# STM32H7x5 register map
File version: 1.1
CPU: CM7 r0p0, little endian, no MPU, no FPU, 3 interrupt priority bits
Registers are 32-bit, read-write, reset 0x0 unless marked. A register's access mark holds for its fields unless they carry their own. Offsets are from the block's base; [hi:lo] are bit positions; {n}, {i} and the like mark numbered series; 'fields as' and 'values as' point back to an identical list.

## BDMA
Base 0x58025400
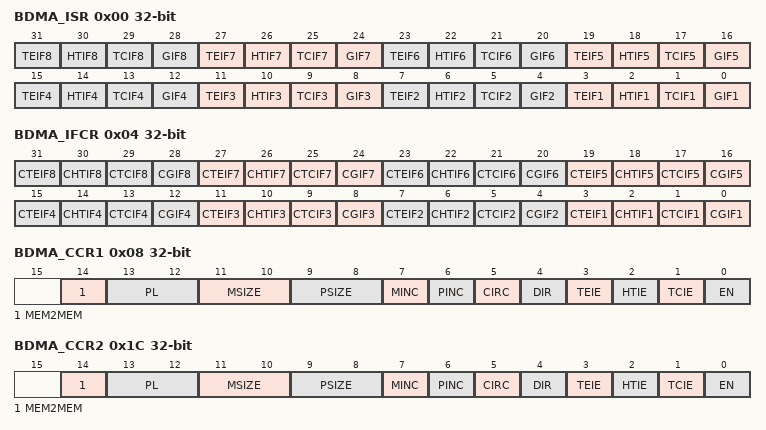
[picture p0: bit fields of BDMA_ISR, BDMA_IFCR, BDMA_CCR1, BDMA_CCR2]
0x00 BDMA_ISR ro — DMA interrupt status register
  [4n-1] TEIF{n} (n=1..8) — Channel x transfer error flag (x = 1..8) This bit is set by hardware. It is cleared by software writing 1 to the corresponding bit in the DMA_IFCR register.
  [4n-2] HTIF{n} (n=1..8) — Channel x half transfer flag (x = 1..8) This bit is set by hardware. It is cleared by software writing 1 to the corresponding bit in the DMA_IFCR register.
  [4n-3] TCIF{n} (n=1..8) — Channel x transfer complete flag (x = 1..8) This bit is set by hardware. It is cleared by software writing 1 to the corresponding bit in the DMA_IFCR register.
  [4n-4] GIF{n} (n=1..8) — Channel x global interrupt flag (x = 1..8) This bit is set by hardware. It is cleared by software writing 1 to the corresponding bit in the DMA_IFCR register.
0x04 BDMA_IFCR wo — DMA interrupt flag clear register
  [4n-1] CTEIF{n} (n=1..8) — Channel x transfer error clear This bit is set and cleared by software.
  [4n-2] CHTIF{n} (n=1..8) — Channel x half transfer clear This bit is set and cleared by software.
  [4n-3] CTCIF{n} (n=1..8) — Channel x transfer complete clear This bit is set and cleared by software.
  [4n-4] CGIF{n} (n=1..8) — Channel x global interrupt clear This bit is set and cleared by software.
0x08 BDMA_CCR1 — DMA channel x configuration register
  [14] MEM2MEM — Memory to memory mode This bit is set and cleared by software.
  [13:12] PL — Channel priority level These bits are set and cleared by software.
  [11:10] MSIZE — Memory size These bits are set and cleared by software.
  [9:8] PSIZE — Peripheral size These bits are set and cleared by software.
  [7] MINC — Memory increment mode This bit is set and cleared by software.
  [6] PINC — Peripheral increment mode This bit is set and cleared by software.
  [5] CIRC — Circular mode This bit is set and cleared by software.
  [4] DIR — Data transfer direction This bit is set and cleared by software.
  [3] TEIE — Transfer error interrupt enable This bit is set and cleared by software.
  [2] HTIE — Half transfer interrupt enable This bit is set and cleared by software.
  [1] TCIE — Transfer complete interrupt enable This bit is set and cleared by software.
  [0] EN — Channel enable This bit is set and cleared by software.
0x0C BDMA_CNDTR1 — DMA channel x number of data register
  [15:0] NDT — Number of data to transfer Number of data to be transferred (0 up to 65535). This register can only be written when the channel is disabled. Once the channel is enabled, this register is read-only, indicating the remaining bytes to be transmitted. This register decrements after each DMA transfer. Once the transfer is completed, this register can either stay at zero or be reloaded automatically by the value previously programmed if the channel is configured in auto-reload mode. If this register is zero, no transaction can be served whether the channel is enabled or not.
0x10 BDMA_CPAR1 — This register must not be written when the channel is enabled.
  [31:0] PA — Peripheral address Base address of the peripheral data register from/to which the data will be read/written. When PSIZE is 01 (16-bit), the PA[0] bit is ignored. Access is automatically aligned to a half-word address. When PSIZE is 10 (32-bit), PA[1:0] are ignored. Access is automatically aligned to a word address.
{0x0+0x14*i} BDMA_CMAR{i} (i=1..8) — This register must not be written when the channel is enabled.
  [31:0] MA — Memory address Base address of the memory area from/to which the data will be read/written. When MSIZE is 01 (16-bit), the MA[0] bit is ignored. Access is automatically aligned to a half-word address. When MSIZE is 10 (32-bit), MA[1:0] are ignored. Access is automatically aligned to a word address.
0x1C BDMA_CCR2 — DMA channel x configuration register
  fields as BDMA_CCR1
0x20 BDMA_CNDTR2 — DMA channel x number of data register
  fields as BDMA_CNDTR1
0x24 BDMA_CPAR2 — This register must not be written when the channel is enabled.
  fields as BDMA_CPAR1
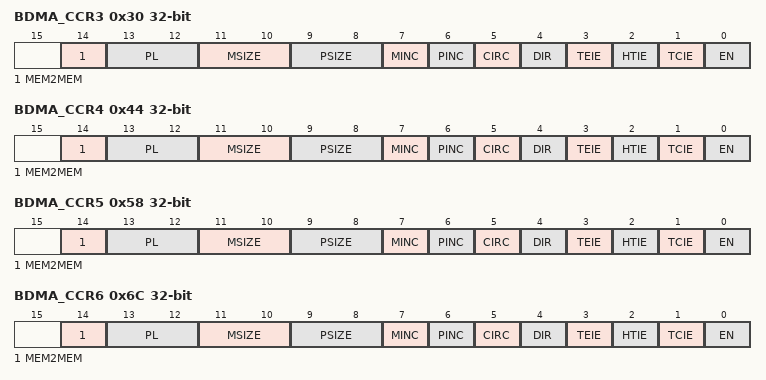
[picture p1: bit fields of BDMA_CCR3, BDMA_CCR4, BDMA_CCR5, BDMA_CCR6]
0x30 BDMA_CCR3 — DMA channel x configuration register
  fields as BDMA_CCR1
0x34 BDMA_CNDTR3 — DMA channel x number of data register
  fields as BDMA_CNDTR1
0x38 BDMA_CPAR3 — This register must not be written when the channel is enabled.
  fields as BDMA_CPAR1
0x44 BDMA_CCR4 — DMA channel x configuration register
  fields as BDMA_CCR1
0x48 BDMA_CNDTR4 — DMA channel x number of data register
  fields as BDMA_CNDTR1
0x4C BDMA_CPAR4 — This register must not be written when the channel is enabled.
  fields as BDMA_CPAR1
0x58 BDMA_CCR5 — DMA channel x configuration register
  fields as BDMA_CCR1
0x5C BDMA_CNDTR5 — DMA channel x number of data register
  fields as BDMA_CNDTR1
0x60 BDMA_CPAR5 — This register must not be written when the channel is enabled.
  fields as BDMA_CPAR1
0x6C BDMA_CCR6 — DMA channel x configuration register
  fields as BDMA_CCR1
0x70 BDMA_CNDTR6 — DMA channel x number of data register
  fields as BDMA_CNDTR1
0x74 BDMA_CPAR6 — This register must not be written when the channel is enabled.
  fields as BDMA_CPAR1
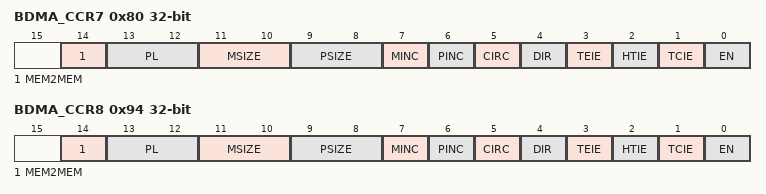
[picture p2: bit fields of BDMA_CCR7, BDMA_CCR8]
0x80 BDMA_CCR7 — DMA channel x configuration register
  fields as BDMA_CCR1
0x84 BDMA_CNDTR7 — DMA channel x number of data register
  fields as BDMA_CNDTR1
0x88 BDMA_CPAR7 — This register must not be written when the channel is enabled.
  fields as BDMA_CPAR1
0x94 BDMA_CCR8 — DMA channel x configuration register
  fields as BDMA_CCR1
0x98 BDMA_CNDTR8 — DMA channel x number of data register
  fields as BDMA_CNDTR1
0x9C BDMA_CPAR8 — This register must not be written when the channel is enabled.
  fields as BDMA_CPAR1
